# bao1x register map
Vendor: baochip; File version: 1.0
Registers are 32-bit, read-write, reset 0x0 unless marked. A register's access mark holds for its fields unless they carry their own. Offsets are from the block's base; [hi:lo] are bit positions; <NAME> marks a mode.

## UDMA_SPIM_0
Base 0x50105000
Same registers: UDMA_SPIM_1 0x50106000, UDMA_SPIM_2 0x50107000, UDMA_SPIM_3 0x50108000
0x00 REG_RX_SADDR — See `udma_spim_reg_if.sv <https://github.com/baochip/baochip-1x/blob/main/rtl/ip s/udma/udma_qspi/rtl/udma_spim_reg_if.sv>`__
  [11:0] r_rx_startaddr
0x04 REG_RX_SIZE — See `udma_spim_reg_if.sv <https://github.com/baochip/baochip-1x/blob/main/rtl/ip s/udma/udma_qspi/rtl/udma_spim_reg_if.sv>`__
  [15:0] r_rx_size
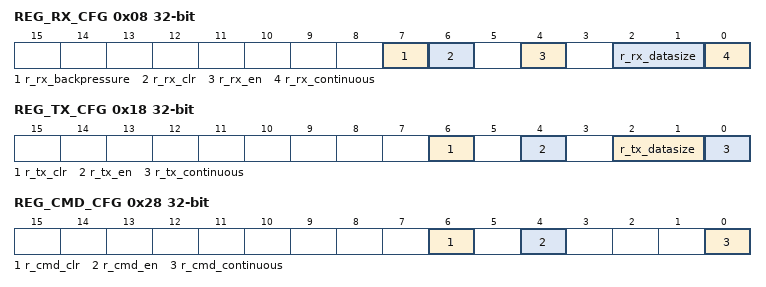
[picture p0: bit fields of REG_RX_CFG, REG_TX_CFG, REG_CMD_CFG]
0x08 REG_RX_CFG — See `udma_spim_reg_if.sv <https://github.com/baochip/baochip-1x/blob/main/rtl/ip s/udma/udma_qspi/rtl/udma_spim_reg_if.sv>`__
  [7] r_rx_backpressure, [6] r_rx_clr, [4] r_rx_en, [2:1] r_rx_datasize, [0] r_rx_continuous
0x10 REG_TX_SADDR — See `udma_spim_reg_if.sv <https://github.com/baochip/baochip-1x/blob/main/rtl/ip s/udma/udma_qspi/rtl/udma_spim_reg_if.sv>`__
  [11:0] r_tx_startaddr
0x14 REG_TX_SIZE — See `udma_spim_reg_if.sv <https://github.com/baochip/baochip-1x/blob/main/rtl/ip s/udma/udma_qspi/rtl/udma_spim_reg_if.sv>`__
  [15:0] r_tx_size
0x18 REG_TX_CFG — See `udma_spim_reg_if.sv <https://github.com/baochip/baochip-1x/blob/main/rtl/ip s/udma/udma_qspi/rtl/udma_spim_reg_if.sv>`__
  [6] r_tx_clr, [4] r_tx_en, [2:1] r_tx_datasize, [0] r_tx_continuous
0x20 REG_CMD_SADDR — See `udma_spim_reg_if.sv <https://github.com/baochip/baochip-1x/blob/main/rtl/ip s/udma/udma_qspi/rtl/udma_spim_reg_if.sv>`__
  [11:0] r_cmd_startaddr
0x24 REG_CMD_SIZE — See `udma_spim_reg_if.sv <https://github.com/baochip/baochip-1x/blob/main/rtl/ip s/udma/udma_qspi/rtl/udma_spim_reg_if.sv>`__
  [15:0] r_cmd_size
0x28 REG_CMD_CFG — See `udma_spim_reg_if.sv <https://github.com/baochip/baochip-1x/blob/main/rtl/ip s/udma/udma_qspi/rtl/udma_spim_reg_if.sv>`__
  [6] r_cmd_clr, [4] r_cmd_en, [0] r_cmd_continuous
0x30 REG_STATUS — See `udma_spim_reg_if.sv <https://github.com/baochip/baochip-1x/blob/main/rtl/ip s/udma/udma_qspi/rtl/udma_spim_reg_if.sv>`__
  [0] status_i

## UDMA_I2C_0
Base 0x50109000
Same registers: UDMA_I2C_1 0x5010A000, UDMA_I2C_2 0x5010B000, UDMA_I2C_3 0x5010C000
0x00 REG_RX_SADDR — See `udma_i2c_reg_if.sv <https://github.com/baochip/baochip-1x/blob/main/rtl/ips /udma/udma_i2c/rtl/udma_i2c_reg_if.sv>`__
  [11:0] r_rx_startaddr
0x04 REG_RX_SIZE — See `udma_i2c_reg_if.sv <https://github.com/baochip/baochip-1x/blob/main/rtl/ips /udma/udma_i2c/rtl/udma_i2c_reg_if.sv>`__
  [15:0] r_rx_size
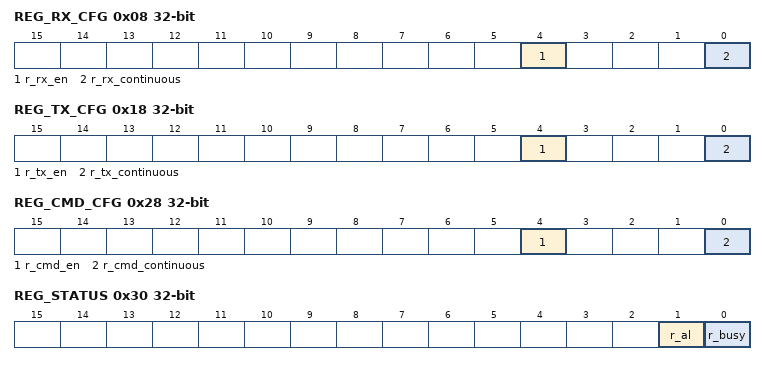
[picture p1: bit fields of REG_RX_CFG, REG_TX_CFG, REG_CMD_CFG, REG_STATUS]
0x08 REG_RX_CFG — See `udma_i2c_reg_if.sv <https://github.com/baochip/baochip-1x/blob/main/rtl/ips /udma/udma_i2c/rtl/udma_i2c_reg_if.sv>`__
  [4] r_rx_en, [0] r_rx_continuous
0x10 REG_TX_SADDR — See `udma_i2c_reg_if.sv <https://github.com/baochip/baochip-1x/blob/main/rtl/ips /udma/udma_i2c/rtl/udma_i2c_reg_if.sv>`__
  [11:0] r_tx_startaddr
0x14 REG_TX_SIZE — See `udma_i2c_reg_if.sv <https://github.com/baochip/baochip-1x/blob/main/rtl/ips /udma/udma_i2c/rtl/udma_i2c_reg_if.sv>`__
  [15:0] r_tx_size
0x18 REG_TX_CFG — See `udma_i2c_reg_if.sv <https://github.com/baochip/baochip-1x/blob/main/rtl/ips /udma/udma_i2c/rtl/udma_i2c_reg_if.sv>`__
  [4] r_tx_en, [0] r_tx_continuous
0x20 REG_CMD_SADDR — See `udma_i2c_reg_if.sv <https://github.com/baochip/baochip-1x/blob/main/rtl/ips /udma/udma_i2c/rtl/udma_i2c_reg_if.sv>`__
  [11:0] r_cmd_startaddr
0x24 REG_CMD_SIZE — See `udma_i2c_reg_if.sv <https://github.com/baochip/baochip-1x/blob/main/rtl/ips /udma/udma_i2c/rtl/udma_i2c_reg_if.sv>`__
  [15:0] r_cmd_size
0x28 REG_CMD_CFG — See `udma_i2c_reg_if.sv <https://github.com/baochip/baochip-1x/blob/main/rtl/ips /udma/udma_i2c/rtl/udma_i2c_reg_if.sv>`__
  [4] r_cmd_en, [0] r_cmd_continuous
0x30 REG_STATUS — See `udma_i2c_reg_if.sv <https://github.com/baochip/baochip-1x/blob/main/rtl/ips /udma/udma_i2c/rtl/udma_i2c_reg_if.sv>`__
  [1] r_al, [0] r_busy
0x38 REG_ACK — See `udma_i2c_reg_if.sv <https://github.com/baochip/baochip-1x/blob/main/rtl/ips /udma/udma_i2c/rtl/udma_i2c_reg_if.sv>`__
  [0] r_nack
